# STM32H753x register map
File version: 1.0
CPU: CM7 r0p1, little endian, MPU, FPU, 4 interrupt priority bits
Registers are 32-bit, read-write, reset 0x0 unless marked. A register's access mark holds for its fields unless they carry their own. Offsets are from the block's base; [hi:lo] are bit positions; {n}, {i} and the like mark numbered series.

## OTG1_HS_PWRCLK — USB 1 on the go high speed
Base 0x40040E00
Same registers: OTG2_HS_PWRCLK 0x40080E00
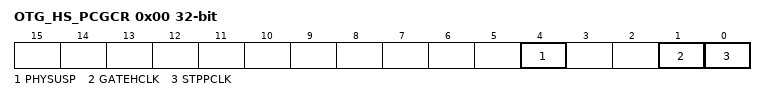
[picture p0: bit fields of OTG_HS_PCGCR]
0x00 OTG_HS_PCGCR — Power and clock gating control register
  [4] PHYSUSP — PHY suspended
  [1] GATEHCLK
  [0] STPPCLK — Stop PHY clock

## Ethernet_MTL — Ethernet: MTL mode register (MTL)
Base 0x40028C00
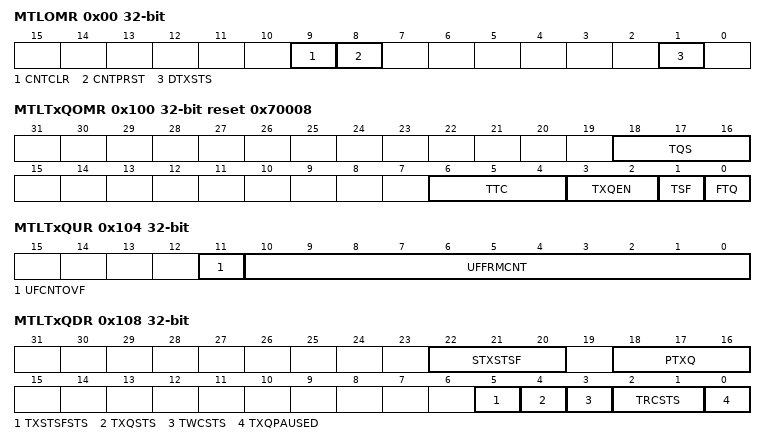
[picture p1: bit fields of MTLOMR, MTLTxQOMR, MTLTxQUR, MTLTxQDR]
0x00 MTLOMR — Operating mode Register
  [9] CNTCLR, [8] CNTPRST, [1] DTXSTS
0x20 MTLISR ro — Interrupt status Register
  [0] Q0IS — Queue interrupt status
0x100 MTLTxQOMR access per field reset 0x70008 — Tx queue operating mode Register
  [18:16] TQS rw — Transmit Queue Size
  [6:4] TTC rw — Transmit Threshold Control
  [3:2] TXQEN ro — Transmit Queue Enable
  [1] TSF rw — Transmit Store and Forward
  [0] FTQ rw — Flush Transmit Queue
0x104 MTLTxQUR ro — Tx queue underflow register
  [11] UFCNTOVF
  [10:0] UFFRMCNT — Underflow Packet Counter
0x108 MTLTxQDR ro — Tx queue debug Register
  [22:20] STXSTSF, [18:16] PTXQ, [5] TXSTSFSTS, [4] TXQSTS, [3] TWCSTS, [2:1] TRCSTS, [0] TXQPAUSED
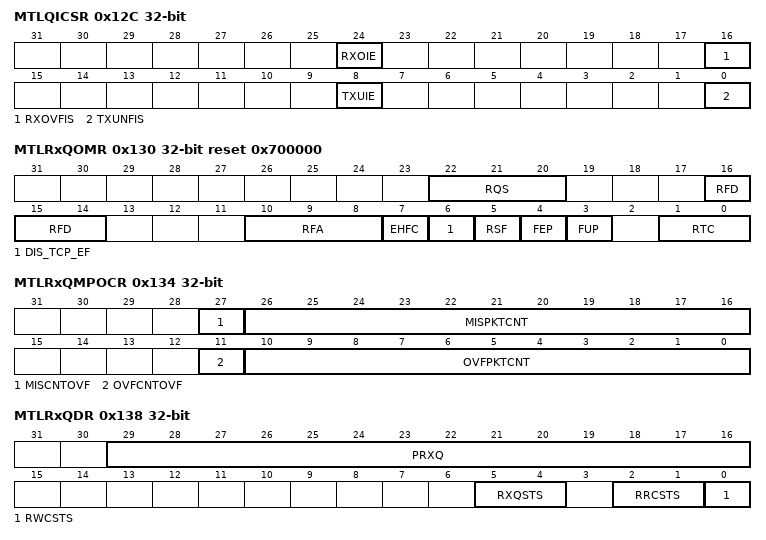
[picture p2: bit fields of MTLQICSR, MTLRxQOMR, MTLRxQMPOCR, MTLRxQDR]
0x12C MTLQICSR — Queue interrupt control status Register
  [24] RXOIE, [16] RXOVFIS, [8] TXUIE, [0] TXUNFIS
0x130 MTLRxQOMR access per field reset 0x700000 — Rx queue operating mode register
  [22:20] RQS ro, [16:14] RFD rw, [10:8] RFA rw, [7] EHFC rw, [6] DIS_TCP_EF rw, [5] RSF rw, [4] FEP rw, [3] FUP rw, [1:0] RTC rw
0x134 MTLRxQMPOCR ro — Rx queue missed packet and overflow counter register
  [27] MISCNTOVF, [26:16] MISPKTCNT, [11] OVFCNTOVF, [10:0] OVFPKTCNT
0x138 MTLRxQDR ro — Rx queue debug register
  [29:16] PRXQ, [5:4] RXQSTS, [2:1] RRCSTS, [0] RWCSTS

## HRTIM_Master — High Resolution Timer: Master Timers
Base 0x40017400
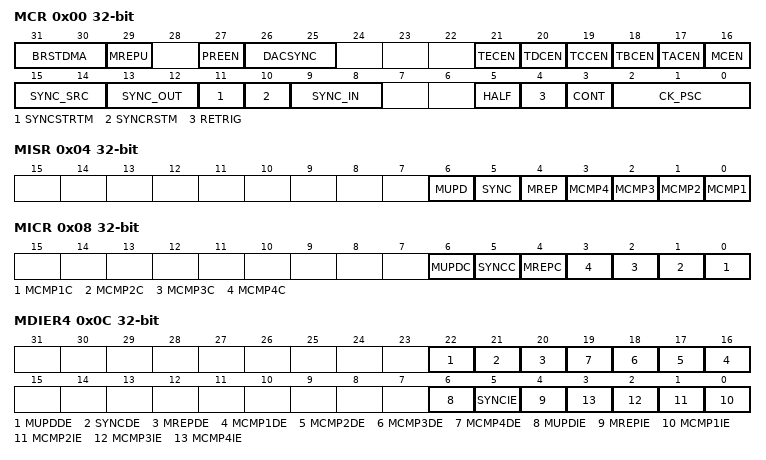
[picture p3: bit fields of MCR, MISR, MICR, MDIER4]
0x00 MCR — Master Timer Control Register
  [31:30] BRSTDMA — Burst DMA Update
  [29] MREPU — Master Timer Repetition update
  [27] PREEN — Preload enable
  [26:25] DACSYNC — AC Synchronization
  [21] TECEN — Timer E counter enable
  [20] TDCEN — Timer D counter enable
  [19] TCCEN — Timer C counter enable
  [18] TBCEN — Timer B counter enable
  [17] TACEN — Timer A counter enable
  [16] MCEN — Master Counter enable
  [15:14] SYNC_SRC — Synchronization source
  [13:12] SYNC_OUT — Synchronization output
  [11] SYNCSTRTM — Synchronization Starts Master
  [10] SYNCRSTM — Synchronization Resets Master
  [9:8] SYNC_IN — ynchronization input
  [5] HALF — Half mode enable
  [4] RETRIG — Master Re-triggerable mode
  [3] CONT — Master Continuous mode
  [2:0] CK_PSC — HRTIM Master Clock prescaler
0x04 MISR ro — Master Timer Interrupt Status Register
  [6] MUPD — Master Update Interrupt Flag
  [5] SYNC — Sync Input Interrupt Flag
  [4] MREP — Master Repetition Interrupt Flag
  [n-1] MCMP{n} (n=1..4) — Master Compare {n} Interrupt Flag
0x08 MICR wo — Master Timer Interrupt Clear Register
  [6] MUPDC — Master update Interrupt flag clear
  [5] SYNCC — Sync Input Interrupt flag clear
  [4] MREPC — Repetition Interrupt flag clear
  [n-1] MCMP{n}C (n=1..4) — Master Compare {n} Interrupt flag clear
0x0C MDIER4
  [22] MUPDDE, [21] SYNCDE, [20] MREPDE, [n+15] MCMP{n}DE (n=1..4), [6] MUPDIE, [5] SYNCIE, [4] MREPIE, [n-1] MCMP{n}IE (n=1..4)
0x10 MCNTR — Master Timer Counter Register
  [15:0] MCNT — Counter value
0x14 MPER reset 0xFFFF — Master Timer Period Register
  [15:0] MPER — Master Timer Period value
0x18 MREP — Master Timer Repetition Register
  [7:0] MREP — Master Timer Repetition counter value
0x1C MCMP1R — Master Timer Compare 1 Register
  [15:0] MCMP1 — Master Timer Compare 1 value
{0x1C+4i} MCMP{i}R (i=2..4) — Master Timer Compare {i} Register
  [15:0] MCMP{i} — Master Timer Compare {i} value

## TIM16 — General-purpose-timers
Base 0x40014400
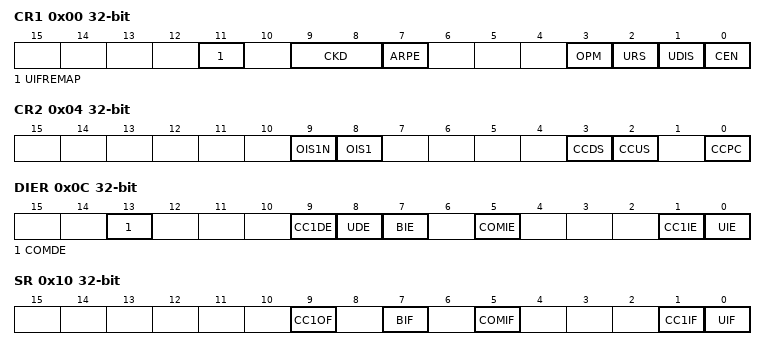
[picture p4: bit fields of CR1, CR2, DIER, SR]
0x00 CR1 — control register 1
  [11] UIFREMAP — UIF status bit remapping
  [9:8] CKD — Clock division
  [7] ARPE — Auto-reload preload enable
  [3] OPM — One-pulse mode
  [2] URS — Update request source
  [1] UDIS — Update disable
  [0] CEN — Counter enable
0x04 CR2 — control register 2
  [9] OIS1N — Output Idle state 1
  [8] OIS1 — Output Idle state 1
  [3] CCDS — Capture/compare DMA selection
  [2] CCUS — Capture/compare control update selection
  [0] CCPC — Capture/compare preloaded control
0x0C DIER — DMA/Interrupt enable register
  [13] COMDE — COM DMA request enable
  [9] CC1DE — Capture/Compare 1 DMA request enable
  [8] UDE — Update DMA request enable
  [7] BIE — Break interrupt enable
  [5] COMIE — COM interrupt enable
  [1] CC1IE — Capture/Compare 1 interrupt enable
  [0] UIE — Update interrupt enable
0x10 SR — status register
  [9] CC1OF — Capture/Compare 1 overcapture flag
  [7] BIF — Break interrupt flag
  [5] COMIF — COM interrupt flag
  [1] CC1IF — Capture/compare 1 interrupt flag
  [0] UIF — Update interrupt flag
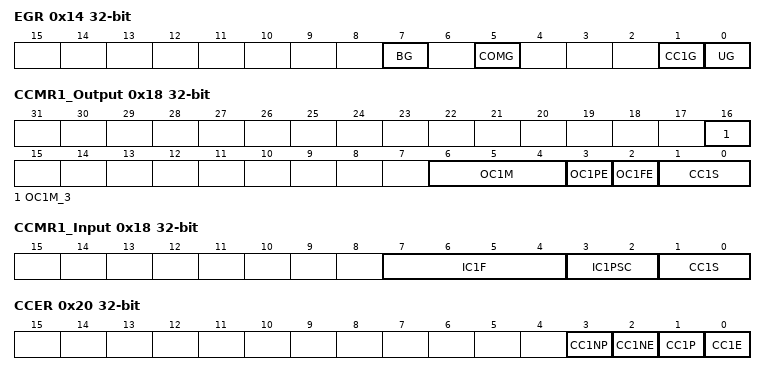
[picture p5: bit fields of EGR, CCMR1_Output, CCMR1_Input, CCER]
0x14 EGR wo — event generation register
  [7] BG — Break generation
  [5] COMG — Capture/Compare control update generation
  [1] CC1G — Capture/compare 1 generation
  [0] UG — Update generation
0x18 CCMR1_Output — capture/compare mode register (output mode)
  [16] OC1M_3 — Output Compare 1 mode
  [6:4] OC1M — Output Compare 1 mode
  [3] OC1PE — Output Compare 1 preload enable
  [2] OC1FE — Output Compare 1 fast enable
  [1:0] CC1S — Capture/Compare 1 selection
0x18 CCMR1_Input (alternate view of CCMR1_Output) — capture/compare mode register 1 (input mode)
  [7:4] IC1F — Input capture 1 filter
  [3:2] IC1PSC — Input capture 1 prescaler
  [1:0] CC1S — Capture/Compare 1 selection
0x20 CCER — capture/compare enable register
  [3] CC1NP — Capture/Compare 1 output Polarity
  [2] CC1NE — Capture/Compare 1 complementary output enable
  [1] CC1P — Capture/Compare 1 output Polarity
  [0] CC1E — Capture/Compare 1 output enable
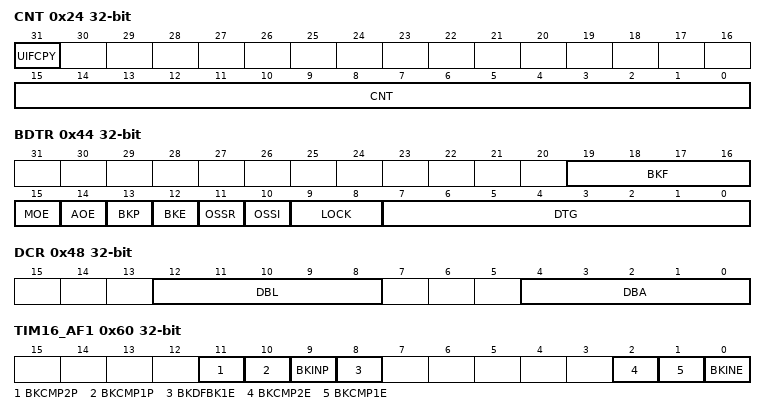
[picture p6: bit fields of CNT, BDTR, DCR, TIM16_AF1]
0x24 CNT access per field — counter
  [31] UIFCPY ro — UIF Copy
  [15:0] CNT rw — counter value
0x28 PSC — prescaler
  [15:0] PSC — Prescaler value
0x2C ARR — auto-reload register
  [15:0] ARR — Auto-reload value
0x30 RCR — repetition counter register
  [7:0] REP — Repetition counter value
0x34 CCR1 — capture/compare register 1
  [15:0] CCR1 — Capture/Compare 1 value
0x44 BDTR — break and dead-time register
  [19:16] BKF — Break filter
  [15] MOE — Main output enable
  [14] AOE — Automatic output enable
  [13] BKP — Break polarity
  [12] BKE — Break enable
  [11] OSSR — Off-state selection for Run mode
  [10] OSSI — Off-state selection for Idle mode
  [9:8] LOCK — Lock configuration
  [7:0] DTG — Dead-time generator setup
0x48 DCR — DMA control register
  [12:8] DBL — DMA burst length
  [4:0] DBA — DMA base address
0x4C DMAR — DMA address for full transfer
  [15:0] DMAB — DMA register for burst accesses
0x60 TIM16_AF1 — TIM16 alternate function register 1
  [11] BKCMP2P — BRK COMP2 input polarity
  [10] BKCMP1P — BRK COMP1 input polarity
  [9] BKINP — BRK BKIN input polarity
  [8] BKDFBK1E — BRK dfsdm1_break[1] enable
  [2] BKCMP2E — BRK COMP2 enable
  [1] BKCMP1E — BRK COMP1 enable
  [0] BKINE — BRK BKIN input enable
0x68 TIM16_TISEL — TIM16 input selection register
  [3:0] TI1SEL — selects TI1[0] to TI1[15] input

## TIM17 — General-purpose-timers
Base 0x40014800
Registers as TIM16 (with TIM16 read as TIM17).
